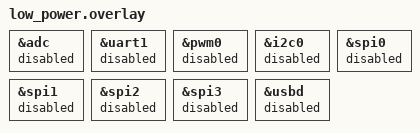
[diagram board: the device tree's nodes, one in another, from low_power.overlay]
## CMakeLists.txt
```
#
# Copyright (c) 2020 Nordic Semiconductor ASA
#
# SPDX-License-Identifier: LicenseRef-Nordic-5-Clause
#
cmake_minimum_required(VERSION 3.20.0)

find_package(Zephyr REQUIRED HINTS $ENV{ZEPHYR_BASE})

project(openthread_cli)

# NORDIC SDK APP START
target_sources(app PRIVATE src/main.c)
# NORDIC SDK APP END

target_sources_ifdef(CONFIG_CLI_SAMPLE_MULTIPROTOCOL app PRIVATE src/ble.c)
target_sources_ifdef(CONFIG_CLI_SAMPLE_LOW_POWER app PRIVATE src/low_power.c)

if(CONFIG_CLI_SAMPLE_MULTIPROTOCOL AND CONFIG_OPENTHREAD_BLE_TCAT)
  message(FATAL_ERROR "Multiprotocol support and TCAT functionality are not compatible." )
endif()

# Do not include obfuscated symbols in case of building from sources
if (CONFIG_MPSL_BUILD_TYPE_SRC_DEBUG)
  target_compile_definitions(nrf-802154-driver-interface INTERFACE OBFUSCATE_LIBMPSL_PROTOCOL_DEFINES_H__=1)
endif()
```

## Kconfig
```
#
# Copyright (c) 2020 Nordic Semiconductor ASA
#
# SPDX-License-Identifier: LicenseRef-Nordic-5-Clause
#

# Set product string for USB device
config CDC_ACM_SERIAL_PRODUCT_STRING
	default "Thread CLI"
	depends on USB_DEVICE_STACK_NEXT

menu "Zephyr Kernel"
source "Kconfig.zephyr"
endmenu

module = OT_COMMAND_LINE_INTERFACE
module-str = ot_cli
source "$(ZEPHYR_BASE)/subsys/logging/Kconfig.template.log_config"

config CLI_SAMPLE_LOW_POWER
	bool "Low power mode for the CLI sample"

config CLI_SAMPLE_LOW_POWER_KEEP_CONSOLE_ALIVE
	bool "Keep console while using low power mode"
	depends on CLI_SAMPLE_LOW_POWER
	help
	  This debug configuration keeps the console active when a CLI device connects to
	  a Thread network. If disabled, the console automatically turns off when a device
	  in SED or SSED mode joins the network.

config CLI_SAMPLE_MULTIPROTOCOL
	bool "Multiprotocol for the CLI sample"
```

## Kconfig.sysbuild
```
#
# Copyright (c) 2024 Nordic Semiconductor ASA
#
# SPDX-License-Identifier: LicenseRef-Nordic-5-Clause
#

config NRF_DEFAULT_IPC_RADIO
	default y if SOC_SERIES_NRF53

config NETCORE_IPC_RADIO_IEEE802154
	default y if SOC_SERIES_NRF53

source "share/sysbuild/Kconfig"
```

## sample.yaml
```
sample:
  name: OpenThread CLI sample
  description: Test OpenThread Command Line Interface.

tests:
  sample.openthread.cli.ite:
    sysbuild: true
    build_only: true
    tags:
      - ci_build
      - sysbuild
      - ci_samples_openthread
    extra_args:
      - cli_SNIPPET="ot-ci;ot-logging"
      - EXTRA_CONF_FILE=extra_conf/tcp.conf
      - CONFIG_OTPERF=y
      - CONFIG_OPENTHREAD_SOURCES=y
    platform_allow:
      - nrf54lm20dk/nrf54lm20a/cpuapp/ite
    integration_platforms:
      - nrf54lm20dk/nrf54lm20a/cpuapp/ite
  sample.openthread.cli:
    sysbuild: true
    build_only: true
    tags:
      - ci_build
      - sysbuild
      - ci_samples_openthread
    extra_args:
      - CONFIG_OPENTHREAD_SOURCES=y
    platform_allow:
      - nrf5340dk/nrf5340/cpuapp
      - nrf54l15dk/nrf54l15/cpuapp
      - nrf54l15dk/nrf54l10/cpuapp
      - nrf54l15dk/nrf54l15/cpuapp/ns
      - nrf54lm20dk/nrf54lm20b/cpuapp
      - nrf54lm20dk/nrf54lm20a/cpuapp
      - nrf54lc10dk/nrf54lc10a/cpuapp
      - nrf54lm20dk/nrf54lm20a/cpuapp/ite
    integration_platforms:
      - nrf5340dk/nrf5340/cpuapp
      - nrf54l15dk/nrf54l15/cpuapp
      - nrf54l15dk/nrf54l10/cpuapp
      - nrf54l15dk/nrf54l15/cpuapp/ns
      - nrf54lm20dk/nrf54lm20b/cpuapp
      - nrf54lm20dk/nrf54lm20a/cpuapp
      - nrf54lc10dk/nrf54lc10a/cpuapp
      - nrf54lm20dk/nrf54lm20a/cpuapp/ite
  sample.openthread.cli.multiprotocol:
    sysbuild: true
    build_only: true
    tags:
      - ci_build
      - sysbuild
      - ci_samples_openthread
    platform_allow:
      - nrf5340dk/nrf5340/cpuapp
      - nrf54l15dk/nrf54l15/cpuapp
      - nrf54l15dk/nrf54l10/cpuapp
      - nrf54l15dk/nrf54l15/cpuapp/ns
      - nrf54lm20dk/nrf54lm20b/cpuapp
      - nrf54lm20dk/nrf54lm20a/cpuapp
      - nrf54lc10dk/nrf54lc10a/cpuapp
      - nrf54lm20dongle/nrf54lm20b/cpuapp
    extra_args:
      - cli_SNIPPET="ot-ci;ot-logging"
      - EXTRA_CONF_FILE="extra_conf/multiprotocol.conf;extra_conf/tcp.conf"
      - CONFIG_OTPERF=y
      - FILE_SUFFIX=ble
    integration_platforms:
      - nrf5340dk/nrf5340/cpuapp
      - nrf54l15dk/nrf54l15/cpuapp
      - nrf54l15dk/nrf54l10/cpuapp
      - nrf54l15dk/nrf54l15/cpuapp/ns
      - nrf54lm20dk/nrf54lm20b/cpuapp
      - nrf54lm20dk/nrf54lm20a/cpuapp
      - nrf54lc10dk/nrf54lc10a/cpuapp
      - nrf54lm20dongle/nrf54lm20b/cpuapp
  sample.openthread.cli.singleprotocol:
    sysbuild: true
    build_only: true
    tags:
      - ci_build
      - sysbuild
      - ci_samples_openthread
    platform_allow:
      - nrf5340dk/nrf5340/cpuapp
      - nrf54l15dk/nrf54l15/cpuapp
      - nrf54l15dk/nrf54l10/cpuapp
      - nrf54l15dk/nrf54l15/cpuapp/ns
      - nrf54lm20dk/nrf54lm20b/cpuapp
      - nrf54lm20dk/nrf54lm20a/cpuapp
      - nrf54lc10dk/nrf54lc10a/cpuapp
    extra_args:
      - cli_SNIPPET="ot-ci;ot-logging"
      - EXTRA_CONF_FILE=extra_conf/tcp.conf
      - CONFIG_OTPERF=y
    integration_platforms:
      - nrf5340dk/nrf5340/cpuapp
      - nrf54l15dk/nrf54l15/cpuapp
      - nrf54l15dk/nrf54l10/cpuapp
      - nrf54l15dk/nrf54l15/cpuapp/ns
      - nrf54lm20dk/nrf54lm20b/cpuapp
      - nrf54lm20dk/nrf54lm20a/cpuapp
      - nrf54lc10dk/nrf54lc10a/cpuapp
  sample.openthread.cli.usb:
    sysbuild: true
    build_only: true
    tags:
      - ci_build
      - sysbuild
      - ci_samples_openthread
    platform_allow:
      - nrf5340dk/nrf5340/cpuapp
    extra_args:
      - cli_SNIPPET="ot-ci;ot-logging;ot-usb"
      - EXTRA_CONF_FILE="extra_conf/multiprotocol.conf;extra_conf/tcp.conf"
      - FILE_SUFFIX=ble
    integration_platforms:
      - nrf5340dk/nrf5340/cpuapp
  sample.openthread.cli.low_power:
    sysbuild: true
    build_only: true
    tags:
      - ci_build
      - sysbuild
      - ci_samples_openthread
    platform_allow:
      - nrf5340dk/nrf5340/cpuapp
      - nrf54l15dk/nrf54l15/cpuapp
      - nrf54lm20dk/nrf54lm20b/cpuapp
      - nrf54lm20dk/nrf54lm20a/cpuapp
      - nrf54lc10dk/nrf54lc10a/cpuapp
    extra_args:
      - cli_SNIPPET="ot-ci"
      - EXTRA_CONF_FILE=extra_conf/low_power.conf
      - CONFIG_OTPERF=y
    integration_platforms:
      - nrf5340dk/nrf5340/cpuapp
      - nrf54l15dk/nrf54l15/cpuapp
      - nrf54lm20dk/nrf54lm20b/cpuapp
      - nrf54lm20dk/nrf54lm20a/cpuapp
      - nrf54lc10dk/nrf54lc10a/cpuapp
  # Build integration regression protection.
  sample.nrf_security.openthread.integration:
    sysbuild: true
    build_only: true
    tags:
      - sysbuild
      - ci_samples_openthread
    platform_allow:
      - nrf5340dk/nrf5340/cpuapp
    extra_args:
      - cli_SNIPPET=ot-ci
      - CONFIG_PSA_CRYPTO=y
    integration_platforms:
      - nrf5340dk/nrf5340/cpuapp
  sample.openthread.cli.tcat:
    sysbuild: true
    build_only: true
    tags:
      - ci_build
      - sysbuild
      - ci_samples_openthread
    platform_allow:
      - nrf5340dk/nrf5340/cpuapp
      - nrf54l15dk/nrf54l15/cpuapp
      - nrf54l15dk/nrf54l10/cpuapp
      - nrf54l15dk/nrf54l15/cpuapp/ns
    extra_args:
      - cli_SNIPPET="ot-ci"
      - EXTRA_CONF_FILE=extra_conf/tcat.conf
      - EXTRA_CONF_FILE=extra_conf/tcp.conf
      - CONFIG_OTPERF=y
      - FILE_SUFFIX=ble
    integration_platforms:
      - nrf5340dk/nrf5340/cpuapp
      - nrf54l15dk/nrf54l15/cpuapp
      - nrf54l15dk/nrf54l10/cpuapp
      - nrf54l15dk/nrf54l15/cpuapp/ns
  sample.openthread.cli.diag_gpio:
    sysbuild: true
    build_only: true
    tags:
      - ci_build
      - sysbuild
      - ci_samples_openthread
    platform_allow:
      - nrf5340dk/nrf5340/cpuapp
      - nrf54l15dk/nrf54l15/cpuapp
      - nrf54l15dk/nrf54l10/cpuapp
      - nrf54l15dk/nrf54l15/cpuapp/ns
    extra_args: >
      cli_SNIPPET="ot-diag-gpio"
    integration_platforms:
      - nrf5340dk/nrf5340/cpuapp
      - nrf54l15dk/nrf54l15/cpuapp
      - nrf54l15dk/nrf54l10/cpuapp
      - nrf54l15dk/nrf54l15/cpuapp/ns
  sample.openthread.cli.l2:
    sysbuild: true
    build_only: true
    tags:
      - ci_build
      - sysbuild
      - ci_samples_openthread
    platform_allow:
      - nrf5340dk/nrf5340/cpuapp
      - nrf54l15dk/nrf54l15/cpuapp
      - nrf54l15dk/nrf54l10/cpuapp
      - nrf54lm20dk/nrf54lm20b/cpuapp
      - nrf54lm20dk/nrf54lm20a/cpuapp
      - nrf54l15dk/nrf54l15/cpuapp/ns
      - nrf54lc10dk/nrf54lc10a/cpuapp
    extra_args:
      - cli_SNIPPET="ot-ci;ot-zephyr-l2"
    integration_platforms:
      - nrf5340dk/nrf5340/cpuapp
      - nrf54l15dk/nrf54l15/cpuapp
      - nrf54l15dk/nrf54l10/cpuapp
      - nrf54lm20dk/nrf54lm20b/cpuapp
      - nrf54lm20dk/nrf54lm20a/cpuapp
      - nrf54l15dk/nrf54l15/cpuapp/ns
      - nrf54lc10dk/nrf54lc10a/cpuapp
  sample.openthread.cli.multiprotocol.l2:
    sysbuild: true
    build_only: true
    tags:
      - ci_build
      - sysbuild
      - ci_samples_openthread
    platform_allow:
      - nrf5340dk/nrf5340/cpuapp
      - nrf54l15dk/nrf54l15/cpuapp
      - nrf54l15dk/nrf54l10/cpuapp
      - nrf54lm20dk/nrf54lm20b/cpuapp
      - nrf54lm20dk/nrf54lm20a/cpuapp
      - nrf54l15dk/nrf54l15/cpuapp/ns
      - nrf54lc10dk/nrf54lc10a/cpuapp
    extra_args:
      - cli_SNIPPET="ot-ci;ot-logging;ot-zephyr-l2;zperf"
      - EXTRA_CONF_FILE="extra_conf/l2_logging.conf;extra_conf/multiprotocol.conf"
      - FILE_SUFFIX=ble
    integration_platforms:
      - nrf5340dk/nrf5340/cpuapp
      - nrf54l15dk/nrf54l15/cpuapp
      - nrf54l15dk/nrf54l10/cpuapp
      - nrf54lm20dk/nrf54lm20b/cpuapp
      - nrf54lm20dk/nrf54lm20a/cpuapp
      - nrf54l15dk/nrf54l15/cpuapp/ns
      - nrf54lc10dk/nrf54lc10a/cpuapp
```

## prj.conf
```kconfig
#
# Copyright (c) 2020 Nordic Semiconductor
#
# SPDX-License-Identifier: LicenseRef-Nordic-5-Clause
#

# Enable OpenThread
CONFIG_OPENTHREAD=y

# Network shell
CONFIG_SHELL=y
CONFIG_OPENTHREAD_SHELL=y
CONFIG_SHELL_ARGC_MAX=26
CONFIG_SHELL_CMD_BUFF_SIZE=416

# Enable OpenThread features set
CONFIG_OPENTHREAD_NORDIC_LIBRARY_MASTER=y

CONFIG_GPIO_SHELL=y
```

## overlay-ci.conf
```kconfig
#
# Copyright (c) 2022 Nordic Semiconductor
#
# SPDX-License-Identifier: LicenseRef-Nordic-5-Clause
#

# Disable boot banner
CONFIG_BOOT_BANNER=n

# Shell configuration for CI
CONFIG_SHELL_PROMPT_UART=""
CONFIG_SHELL_VT100_COLORS=n
CONFIG_SHELL_DEFAULT_TERMINAL_WIDTH=618
```

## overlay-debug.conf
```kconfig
#
# Copyright (c) 2022 Nordic Semiconductor
#
# SPDX-License-Identifier: LicenseRef-Nordic-5-Clause
#

# Enable multithread support in gdb
CONFIG_DEBUG=y
CONFIG_THREAD_MONITOR=y
CONFIG_THREAD_STACK_INFO=y
CONFIG_TIMESLICING=n
CONFIG_THREAD_NAME=y
CONFIG_DEBUG_THREAD_INFO=y
CONFIG_OPENTHREAD_SOURCES=y
```

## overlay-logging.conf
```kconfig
#
# Copyright (c) 2021 Nordic Semiconductor
#
# SPDX-License-Identifier: LicenseRef-Nordic-5-Clause
# Enable Zephyr logging
CONFIG_LOG=y

# Use separate thread for logging
CONFIG_LOG_MODE_DEFERRED=y

# Increase max log level to informative
CONFIG_LOG_MAX_LEVEL=3

# Option for configuring log level in this sample
CONFIG_OT_COMMAND_LINE_INTERFACE_LOG_LEVEL_INF=y

# Enable net module logging
# CONFIG_NET_LOG=y
# Option for configuring log level in net config library
# CONFIG_NET_CONFIG_LOG_LEVEL_INF=y

# Option for configuring log level in Zephyr L2 logging
# CONFIG_OPENTHREAD_L2_DEBUG=y
# CONFIG_OPENTHREAD_L2_LOG_LEVEL_DBG=y
# CONFIG_OPENTHREAD_L2_DEBUG_DUMP_15_4=y
# CONFIG_OPENTHREAD_L2_DEBUG_DUMP_IPV6=y

# Enable Mbed TLS logging
# CONFIG_OPENTHREAD_MBEDTLS_DEBUG=y
# CONFIG_MBEDTLS_DEBUG_LEVEL=3

# Enable OpenThread logging
CONFIG_OPENTHREAD_DEBUG=y
# Option for configuring log level in OpenThread
CONFIG_OPENTHREAD_LOG_LEVEL_INFO=y

# Enable RTT logging backend
CONFIG_USE_SEGGER_RTT=y
CONFIG_LOG_BACKEND_RTT=y

# Disable UART logging backend
# CONFIG_LOG_BACKEND_UART=n
CONFIG_SHELL_LOG_BACKEND=n
```

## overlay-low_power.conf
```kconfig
#
# Copyright (c) 2023 Nordic Semiconductor
#
# SPDX-License-Identifier: LicenseRef-Nordic-5-Clause
#

CONFIG_CLI_SAMPLE_LOW_POWER=y
CONFIG_OPENTHREAD_MTD=y
CONFIG_RAM_POWER_DOWN_LIBRARY=y
CONFIG_PM_DEVICE=y

CONFIG_SYSTEM_WORKQUEUE_STACK_SIZE=2048
```

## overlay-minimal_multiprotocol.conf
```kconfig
#
# Copyright (c) 2020 Nordic Semiconductor
#
# SPDX-License-Identifier: LicenseRef-Nordic-5-Clause
#

# Build
CONFIG_SIZE_OPTIMIZATIONS=y

# Boot
CONFIG_BOOT_BANNER=n
CONFIG_BOOT_DELAY=0

# Disable asserts to save ~28kB ROM
CONFIG_ASSERT=n

# Disable logging to save ~11kB ROM
CONFIG_LOG=n
CONFIG_OPENTHREAD_DEBUG=n
CONFIG_OPENTHREAD_L2_DEBUG=n

# Network shell
CONFIG_NET_SHELL=n

# Enable and configure Bluetooth LE
CONFIG_BT=y
CONFIG_BT_PERIPHERAL=y
CONFIG_BT_DEVICE_NAME="NCS DUT"
CONFIG_BT_DEVICE_APPEARANCE=833

# Disable BT Security Manager Protocol support to save ~20kB ROM
# Pairing with the device will not be available, only non-secure connection
CONFIG_BT_SMP=n

# Restrict number of BT connection
CONFIG_BT_MAX_CONN=1

# Disable Bluetooth features not needed
CONFIG_BT_DEBUG_NONE=y
CONFIG_BT_ASSERT=n
CONFIG_BT_DATA_LEN_UPDATE=n
CONFIG_BT_PHY_UPDATE=n
CONFIG_BT_GATT_CACHING=n
CONFIG_BT_GATT_SERVICE_CHANGED=n
CONFIG_BT_GAP_PERIPHERAL_PREF_PARAMS=n
CONFIG_BT_HCI_VS_EXT=n

# # Disable LE Controller-based Privacy
CONFIG_BT_CTLR_PRIVACY=n

# Disable HCI Vendor-Specific Extensions
CONFIG_BT_HCI_VS_EXT=n

# Reduce Bluetooth buffers
CONFIG_BT_BUF_EVT_DISCARDABLE_COUNT=1
CONFIG_BT_BUF_EVT_DISCARDABLE_SIZE=43
CONFIG_BT_BUF_EVT_RX_COUNT=2
CONFIG_BT_CONN_TX_MAX=2
CONFIG_BT_L2CAP_TX_BUF_COUNT=2
CONFIG_BT_CTLR_RX_BUFFERS=1
CONFIG_BT_BUF_ACL_TX_COUNT=3
CONFIG_BT_BUF_ACL_TX_SIZE=27

# To correctly tune the stack sizes for the threads, the following
# configurations can enabled to print the current use:
# CONFIG_THREAD_NAME=y
# CONFIG_THREAD_ANALYZER=y
# CONFIG_THREAD_ANALYZER_AUTO=y
# CONFIG_THREAD_ANALYZER_RUN_UNLOCKED=y
# CONFIG_THREAD_ANALYZER_USE_PRINTK=y
# CONFIG_CONSOLE=y
# CONFIG_UART_CONSOLE=y
# CONFIG_SERIAL=y
# CONFIG_PRINTK=y

# Example output of thread analyzer:
#  SDC RX              : unused 160 usage 200 / 360 (55 %)
#  BT RX               : unused 616 usage 408 / 1024 (39 %)
#  BT TX               : unused 304 usage 336 / 640 (52 %)
#  thread_analyzer     : unused 160 usage 352 / 512 (68 %)
#  rx_workq            : unused 332 usage 180 / 512 (35 %)
#  openthread          : unused 1944 usage 2152 / 4096 (52 %)
#  workqueue           : unused 232 usage 280 / 512 (54 %)
#  tx_workq            : unused 136 usage 120 / 256 (46 %)
#  net_mgmt            : unused 104 usage 152 / 256 (59 %)
#  nrf5_rx             : unused 256 usage 256 / 512 (50 %)
#  sysworkq            : unused 792 usage 232 / 1024 (22 %)
#  MPSL signal         : unused 152 usage 488 / 640 (76 %)
#  shell_uart          : unused 648 usage 1400 / 2048 (68 %)
#  idle 00             : unused 56 usage 72 / 128 (56 %)

# Configurations set based on thread analyzer output.
CONFIG_BT_CTLR_SDC_RX_STACK_SIZE=360
CONFIG_BT_RX_STACK_SIZE=1024
CONFIG_BT_HCI_TX_STACK_SIZE_WITH_PROMPT=y
CONFIG_BT_HCI_TX_STACK_SIZE=640
CONFIG_OPENTHREAD_THREAD_STACK_SIZE=4096
CONFIG_NET_RX_STACK_SIZE=512
CONFIG_NET_TX_STACK_SIZE=256
CONFIG_NET_MGMT_EVENT_STACK_SIZE=256
CONFIG_IEEE802154_NRF5_RX_STACK_SIZE=512
CONFIG_SYSTEM_WORKQUEUE_STACK_SIZE=2144
CONFIG_MPSL_WORK_STACK_SIZE=640
CONFIG_SHELL_STACK_SIZE=2048
CONFIG_IDLE_STACK_SIZE=128
CONFIG_MAIN_STACK_SIZE=2048
CONFIG_ISR_STACK_SIZE=1024
```

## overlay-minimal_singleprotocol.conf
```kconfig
#
# Copyright (c) 2020 Nordic Semiconductor
#
# SPDX-License-Identifier: LicenseRef-Nordic-5-Clause
#

# Build
CONFIG_SIZE_OPTIMIZATIONS=y

# Boot
CONFIG_BOOT_BANNER=n
CONFIG_BOOT_DELAY=0

# Disable asserts to save ~28kB ROM
CONFIG_ASSERT=n

# Disable logging to save ~11kB ROM
CONFIG_LOG=n
CONFIG_OPENTHREAD_DEBUG=n
CONFIG_OPENTHREAD_L2_DEBUG=n

# Network shell
CONFIG_NET_SHELL=n

# To correctly tune the stack sizes for the threads, the following
# configurations can enabled to print the current use:
# CONFIG_THREAD_NAME=y
# CONFIG_THREAD_ANALYZER=y
# CONFIG_THREAD_ANALYZER_AUTO=y
# CONFIG_THREAD_ANALYZER_RUN_UNLOCKED=y
# CONFIG_THREAD_ANALYZER_USE_PRINTK=y
# CONFIG_CONSOLE=y
# CONFIG_UART_CONSOLE=y
# CONFIG_SERIAL=y
# CONFIG_PRINTK=y

# Example output of thread analyzer:
#  thread_analyzer     : unused 160 usage 352 / 512 (68 %)
#  conn_mgr_thread     : unused 136 usage 120 / 256 (46 %)
#  rx_workq            : unused 332 usage 180 / 512 (35 %)
#  openthread          : unused 1944 usage 2152 / 4096 (52 %)
#  workqueue           : unused 232 usage 280 / 512 (54 %)
#  tx_workq            : unused 136 usage 120 / 256 (46 %)
#  net_mgmt            : unused 104 usage 152 / 256 (59 %)
#  nrf5_rx             : unused 256 usage 256 / 512 (50 %)
#  sysworkq            : unused 792 usage 232 / 1024 (22 %)
#  MPSL signal         : unused 152 usage 488 / 640 (76 %)
#  shell_uart          : unused 648 usage 1400 / 2048 (68 %)
#  idle 00             : unused 56 usage 72 / 128 (56 %)

# Configurations set based on thread analyzer output.
CONFIG_OPENTHREAD_THREAD_STACK_SIZE=4096
CONFIG_NET_RX_STACK_SIZE=512
CONFIG_NET_TX_STACK_SIZE=256
CONFIG_NET_MGMT_EVENT_STACK_SIZE=256
CONFIG_IEEE802154_NRF5_RX_STACK_SIZE=512
CONFIG_SYSTEM_WORKQUEUE_STACK_SIZE=1024
CONFIG_MPSL_WORK_STACK_SIZE=640
CONFIG_SHELL_STACK_SIZE=2048
CONFIG_IDLE_STACK_SIZE=128
CONFIG_MAIN_STACK_SIZE=2048
CONFIG_ISR_STACK_SIZE=1024
```

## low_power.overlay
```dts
/*
 * Copyright (c) 2023 Nordic Semiconductor ASA
 *
 * SPDX-License-Identifier: LicenseRef-Nordic-5-Clause
 */

&adc {
	status = "disabled";
};
&uart1 {
	status = "disabled";
};
&pwm0 {
	status = "disabled";
};
&i2c0 {
	status = "disabled";
};
&spi0 {
	status = "disabled";
};
&spi1 {
	status = "disabled";
};
&spi2 {
	status = "disabled";
};
&spi3 {
	status = "disabled";
};
&usbd {
	status = "disabled";
};
```

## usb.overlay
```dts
/*
 * Copyright (c) 2021 Nordic Semiconductor ASA
 *
 * SPDX-License-Identifier: LicenseRef-Nordic-5-Clause
 */

/ {
	chosen {
		zephyr,shell-uart = &cdc_acm_uart;
	};
};

&zephyr_udc0 {
	cdc_acm_uart: cdc_acm_uart {
		compatible = "zephyr,cdc-acm-uart";
	};
};
```

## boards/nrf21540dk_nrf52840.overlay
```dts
/* Copyright (c) 2020 Nordic Semiconductor ASA
 *
 * SPDX-License-Identifier: LicenseRef-Nordic-5-Clause
 */

/* Default Zephyr configuration already provides GPIO support for FEM. */

&uart0 {
	status = "okay";
	hw-flow-control;
};

/ {
	/*
	* In some default configurations within the nRF Connect SDK,
	* e.g. on nRF52840, the chosen zephyr,entropy node is &cryptocell.
	* This devicetree overlay ensures that default is overridden wherever it
	* is set, as this application uses the RNG node for entropy exclusively.
	*/
	chosen {
		zephyr,entropy = &rng;
	};
};
```

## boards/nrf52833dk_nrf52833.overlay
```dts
/* Copyright (c) 2020 Nordic Semiconductor ASA
 *
 * SPDX-License-Identifier: LicenseRef-Nordic-5-Clause
 */

&uart0 {
	status = "okay";
	hw-flow-control;
};

&flash0 {

	partitions {
		compatible = "fixed-partitions";
		#address-cells = <1>;
		#size-cells = <1>;

		storage_partition: partition@7a000 {
			label = "storage";
			reg = <0x0007C000 0x4000>;
		};
	};
};
```

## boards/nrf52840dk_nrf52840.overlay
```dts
/* Copyright (c) 2023 Nordic Semiconductor ASA
 *
 * SPDX-License-Identifier: LicenseRef-Nordic-5-Clause
 */

&mx25r64 {
	status = "disabled";
};

&uart0 {
	status = "okay";
	hw-flow-control;
};

/ {
	/*
	* In some default configurations within the nRF Connect SDK,
	* e.g. on nRF52840, the chosen zephyr,entropy node is &cryptocell.
	* This devicetree overlay ensures that default is overridden wherever it
	* is set, as this application uses the RNG node for entropy exclusively.
	*/
	chosen {
		zephyr,entropy = &rng;
	};
};
```

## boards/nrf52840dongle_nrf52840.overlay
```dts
/* Copyright (c) 2024 Nordic Semiconductor ASA
 *
 * SPDX-License-Identifier: LicenseRef-Nordic-5-Clause
 */

&uart0 {
	status = "okay";
	hw-flow-control;
};

/ {
	/*
	 * nRF52840 dongle has pin P0.19 connected to reset. By setting it
	 * in `GPIO_OUTPUT_ACTIVE` mode, reset is pulled to GND,
	 * which results in device rebooting without skipping the bootloader.
	 * openthread_config node enables doing so using `ot reset bootloader` command.
	 */
	openthread_config: openthread {
		compatible = "openthread,config";
		bootloader-gpios = <&gpio0 19 GPIO_ACTIVE_LOW>;
	};
};
```

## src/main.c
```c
/*
 * Copyright (c) 2020 Nordic Semiconductor ASA
 *
 * SPDX-License-Identifier: LicenseRef-Nordic-5-Clause
 */

#include <zephyr/kernel.h>
#include <zephyr/logging/log.h>

#if defined(CONFIG_CLI_SAMPLE_MULTIPROTOCOL)
#include "ble.h"
#endif

#if defined(CONFIG_CLI_SAMPLE_LOW_POWER)
#include "low_power.h"
#endif

#include <zephyr/drivers/uart.h>

LOG_MODULE_REGISTER(cli_sample, CONFIG_OT_COMMAND_LINE_INTERFACE_LOG_LEVEL);

#define WELLCOME_TEXT \
	"\n\r"\
	"\n\r"\
	"OpenThread Command Line Interface is now running.\n\r" \
	"Use the 'ot' keyword to invoke OpenThread commands e.g. " \
	"'ot thread start.'\n\r" \
	"For the full commands list refer to the OpenThread CLI " \
	"documentation at:\n\r" \
	"https://github.com/openthread/openthread/blob/master/src/cli/README.md\n\r"

int main(void)
{
#if DT_NODE_HAS_COMPAT(DT_CHOSEN(zephyr_shell_uart), zephyr_cdc_acm_uart)
	int ret;
	const struct device *dev;
	uint32_t dtr = 0U;

	dev = DEVICE_DT_GET(DT_CHOSEN(zephyr_shell_uart));
	if (dev == NULL) {
		LOG_ERR("Failed to find specific UART device");
		return 0;
	}

	LOG_INF("Waiting for host to be ready to communicate");

	/* Data Terminal Ready - check if host is ready to communicate */
	while (!dtr) {
		ret = uart_line_ctrl_get(dev, UART_LINE_CTRL_DTR, &dtr);
		if (ret) {
			LOG_ERR("Failed to get Data Terminal Ready line state: %d",
				ret);
			continue;
		}
		k_msleep(100);
	}

	/* Data Carrier Detect Modem - mark connection as established */
	(void)uart_line_ctrl_set(dev, UART_LINE_CTRL_DCD, 1);
	/* Data Set Ready - the NCP SoC is ready to communicate */
	(void)uart_line_ctrl_set(dev, UART_LINE_CTRL_DSR, 1);
#endif

	LOG_INF(WELLCOME_TEXT);

#if defined(CONFIG_CLI_SAMPLE_MULTIPROTOCOL)
	ble_enable();
#endif

#if defined(CONFIG_CLI_SAMPLE_LOW_POWER)
	low_power_enable();
#endif

	return 0;
}
```

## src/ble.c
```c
/*
 * Copyright (c) 2020 Nordic Semiconductor ASA
 *
 * SPDX-License-Identifier: LicenseRef-Nordic-5-Clause
 */

#include <zephyr/kernel.h>
#include <zephyr/bluetooth/gatt.h>

#include "ble.h"

#define DEVICE_NAME CONFIG_BT_DEVICE_NAME
#define DEVICE_NAME_LEN (sizeof(DEVICE_NAME) - 1)

#define ADV_INT_MIN 0x01e0 /* 300 ms */
#define ADV_INT_MAX 0x0260 /* 380 ms */

static const struct bt_data ad[] = {
	BT_DATA_BYTES(BT_DATA_FLAGS, (BT_LE_AD_GENERAL | BT_LE_AD_NO_BREDR)),
	BT_DATA(BT_DATA_NAME_COMPLETE, DEVICE_NAME, DEVICE_NAME_LEN),
};

static struct bt_conn_cb conn_callbacks;

void ble_enable(void)
{
	const struct bt_le_adv_param *adv_param = BT_LE_ADV_PARAM(
		BT_LE_ADV_OPT_CONN, ADV_INT_MIN, ADV_INT_MAX, NULL);

	bt_enable(NULL);
	bt_conn_cb_register(&conn_callbacks);
	bt_le_adv_start(adv_param, ad, ARRAY_SIZE(ad), NULL, 0);
}
```

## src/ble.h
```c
/**
 * @file
 * @defgroup ble Bluetooth LE API
 * @{
 */

/*
 * Copyright (c) 2020 Nordic Semiconductor ASA
 *
 * SPDX-License-Identifier: LicenseRef-Nordic-5-Clause
 */

#ifndef __BLE_H__
#define __BLE_H__

/** @brief Initialize BLE.
 */
void ble_enable(void);

#endif

/**
 * @}
 */
```

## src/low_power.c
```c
/*
 * Copyright (c) 2023 Nordic Semiconductor ASA
 *
 * SPDX-License-Identifier: LicenseRef-Nordic-5-Clause
 */

#include <openthread.h>
#include <openthread/thread.h>
#include <zephyr/device.h>
#include <zephyr/pm/device.h>
#if defined(CONFIG_RAM_POWER_DOWN_LIBRARY)
#include <ram_pwrdn.h>
#endif

#include "low_power.h"

#if !defined(CONFIG_CLI_SAMPLE_LOW_POWER_KEEP_CONSOLE_ALIVE)
static void on_thread_state_changed(otChangedFlags flags, void *user_data)
{
	struct otInstance *instance = openthread_get_default_instance();

	if (flags & OT_CHANGED_THREAD_ROLE) {
		if (otThreadGetDeviceRole(instance) == OT_DEVICE_ROLE_CHILD) {
			const struct device *cons = DEVICE_DT_GET(DT_CHOSEN(zephyr_console));

			if (!device_is_ready(cons)) {
				return;
			}

			pm_device_action_run(cons, PM_DEVICE_ACTION_SUSPEND);
#if defined(CONFIG_RAM_POWER_DOWN_LIBRARY)
			power_down_unused_ram();
#endif
		}
	}
}

static struct openthread_state_changed_callback ot_state_chaged_cb = {
	.otCallback = on_thread_state_changed};
#endif /* !defined(CONFIG_CLI_SAMPLE_LOW_POWER_KEEP_CONSOLE_ALIVE) */

void low_power_enable(void)
{
#if !defined(CONFIG_CLI_SAMPLE_LOW_POWER_KEEP_CONSOLE_ALIVE)
	openthread_state_changed_callback_register(&ot_state_chaged_cb);
#endif /* !defined(CONFIG_CLI_SAMPLE_LOW_POWER_KEEP_CONSOLE_ALIVE) */
}
```

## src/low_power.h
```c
/**
 * @file
 * @defgroup low_power Low Power API
 * @{
 */

/*
 * Copyright (c) 2023 Nordic Semiconductor ASA
 *
 * SPDX-License-Identifier: LicenseRef-Nordic-5-Clause
 */

#ifndef __LOW_POWER_H__
#define __LOW_POWER_H__

/** @brief Initialize Low Power mode.
 */
void low_power_enable(void);

#endif

/**
 * @}
 */
```
